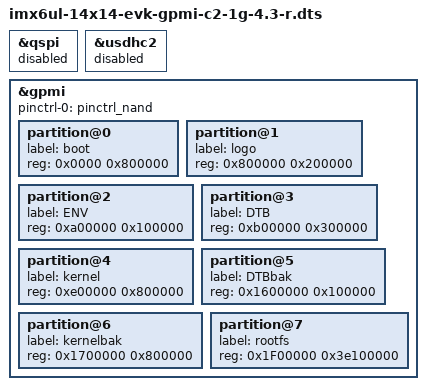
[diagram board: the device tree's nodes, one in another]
/*
 * Copyright (C) 2015 Freescale Semiconductor, Inc.
 *
 * This program is free software; you can redistribute it and/or modify
 * it under the terms of the GNU General Public License version 2 as
 * published by the Free Software Foundation.
 */

#include "imx6ul-14x14-evk-c2-4.3-r.dts"
&qspi{
			status = "disabled";
};

&usdhc2 {
			status = "disabled";
};

&gpmi {
	pinctrl-names = "default";
	pinctrl-0 = <&pinctrl_nand>;
	status = "okay";
	partition@0{
				label = "boot";
				reg = <0x0000 0x800000>; /*8M*/
		};
	partition@1{
				label = "logo";
				reg = <0x800000 0x200000>; /*2M*/
		};
	partition@2{
				label = "ENV";
				reg = <0xa00000 0x100000>; /*1M*/
		};
	partition@3{
				label = "DTB";
				reg = <0xb00000 0x300000>; /*3M*/
		};
	partition@4{
				label = "kernel";
				reg = <0xe00000 0x800000>; /*8M*/
		};
	partition@5{
				label = "DTBbak";
				reg = <0x1600000 0x100000>; /*1M*/
		};
	partition@6{
				label = "kernelbak";
				reg = <0x1700000 0x800000>; /*8M*/
		};
	partition@7{
				label = "rootfs";
				reg = <0x1F00000 0x3e100000>;
		};
};


